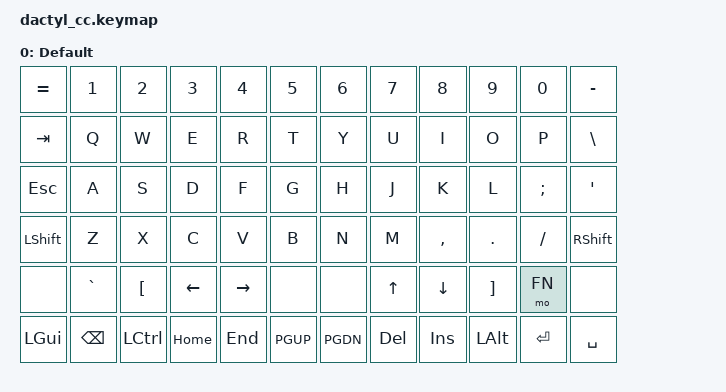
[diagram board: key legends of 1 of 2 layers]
#include <behaviors.dtsi>
#include <dt-bindings/zmk/keys.h>
#include <dt-bindings/zmk/bt.h>
#include <dt-bindings/zmk/outputs.h>

#define DEFAULT 0
#define FN      1

/ {
    keymap {
        compatible = "zmk,keymap";

        default_layer {
            display-name = "Default";
            bindings = <
                /* ROW 0 */
                &kp EQUAL   &kp N1      &kp N2      &kp N3      &kp N4      &kp N5      &kp N6      &kp N7      &kp N8      &kp N9      &kp N0      &kp MINUS
                /* ROW 1 */
                &kp TAB     &kp Q       &kp W       &kp E       &kp R       &kp T       &kp Y       &kp U       &kp I       &kp O       &kp P       &kp BSLH
                /* ROW 2 */
                &kp ESC     &kp A       &kp S       &kp D       &kp F       &kp G       &kp H       &kp J       &kp K       &kp L       &kp SEMI    &kp SQT
                /* ROW 3 */
                &kp LSHFT   &kp Z       &kp X       &kp C       &kp V       &kp B       &kp N       &kp M       &kp COMMA   &kp DOT     &kp FSLH    &kp RSHFT
                /* ROW 4 (8 keys) */
                &none       &kp GRAVE   &kp LBKT    &kp LEFT    &kp RIGHT   &none       &none       &kp UP      &kp DOWN    &kp RBKT    &mo FN      &none
                /* ROW 5 */
                &kp LGUI    &kp BSPC    &kp LCTRL   &kp HOME    &kp END     &kp PGUP    &kp PGDN    &kp DEL     &kp INS     &kp LALT    &kp ENTER   &kp SPACE
            >;
        };

        fn_layer {
            display-name = "FN";
            bindings = <
                /* ROW 0 */
                &kp F1      &kp F2      &kp F3      &kp F4      &kp F5      &kp F6      &kp F7      &kp F8      &kp F9      &kp F10     &kp F11     &kp F12
                /* ROW 1 */
                &bt BT_CLR  &bt BT_SEL 0 &bt BT_SEL 1 &bt BT_SEL 2 &bt BT_SEL 3 &bt BT_SEL 4 &trans      &kp C_PREV  &kp C_PP    &kp C_NEXT  &kp C_VOL_UP &kp C_MUTE
                /* ROW 2 */
                &out OUT_BLE &out OUT_USB &trans     &trans      &trans      &trans      &trans      &trans      &trans      &trans      &kp C_VOL_DN &trans
                /* ROW 3 */
                &trans      &trans      &trans      &trans      &trans      &trans      &trans      &trans      &trans      &trans      &trans      &trans
                /* ROW 4 */
                &trans      &trans      &trans      &trans      &trans      &trans      &trans      &trans
                /* ROW 5 */
                &trans      &trans      &trans      &trans      &trans      &trans      &trans      &trans      &trans      &trans      &trans      &trans
            >;
        };

        /* Leave extra layers for ZMK Studio */
        extra1 { status = "reserved"; };
        extra2 { status = "reserved"; };
    };
};
